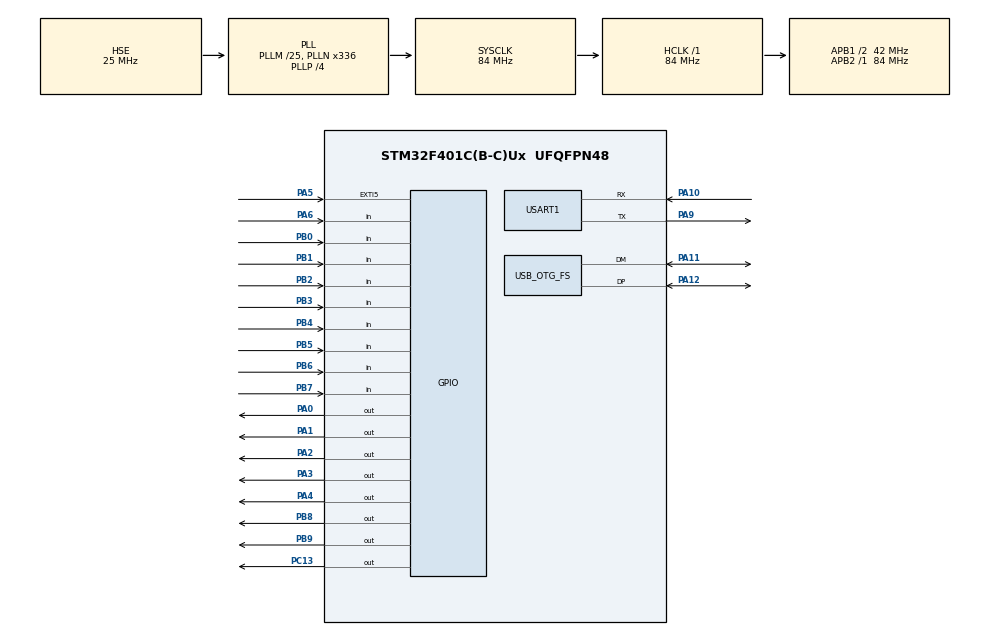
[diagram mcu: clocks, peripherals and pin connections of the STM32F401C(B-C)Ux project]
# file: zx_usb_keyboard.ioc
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Mcu.Family=STM32F4
Mcu.Name=STM32F401C(B-C)Ux
Mcu.Package=UFQFPN48
NVIC.EXTI9_5_IRQn=true\:0\:0\:false\:false\:true\:true\:true\:true
NVIC.OTG_FS_IRQn=true\:1\:0\:true\:false\:true\:false\:true\:true
NVIC.PriorityGroup=NVIC_PRIORITYGROUP_4
PA0-WKUP.GPIO_Speed=GPIO_SPEED_FREQ_VERY_HIGH
PA0-WKUP.PinState=GPIO_PIN_SET
PA0-WKUP.Signal=GPIO_Output
PA1.GPIO_Speed=GPIO_SPEED_FREQ_VERY_HIGH
PA1.PinState=GPIO_PIN_SET
PA1.Signal=GPIO_Output
PA10.Mode=Asynchronous
PA10.Signal=USART1_RX
PA11.Mode=Host_Only
PA11.Signal=USB_OTG_FS_DM
PA12.Mode=Host_Only
PA12.Signal=USB_OTG_FS_DP
PA13.Mode=Serial_Wire
PA13.Signal=SYS_JTMS-SWDIO
PA14.Mode=Serial_Wire
PA14.Signal=SYS_JTCK-SWCLK
PA2.GPIO_Speed=GPIO_SPEED_FREQ_VERY_HIGH
PA2.PinState=GPIO_PIN_SET
PA2.Signal=GPIO_Output
PA3.GPIO_Speed=GPIO_SPEED_FREQ_VERY_HIGH
PA3.PinState=GPIO_PIN_SET
PA3.Signal=GPIO_Output
PA4.GPIO_Speed=GPIO_SPEED_FREQ_VERY_HIGH
PA4.PinState=GPIO_PIN_SET
PA4.Signal=GPIO_Output
PA5.GPIO_ModeDefaultEXTI=GPIO_MODE_IT_FALLING
PA5.Signal=GPXTI5
PA6.Signal=GPIO_Input
PA9.Mode=Asynchronous
PA9.Signal=USART1_TX
PB0.Signal=GPIO_Input
PB1.Signal=GPIO_Input
PB2.Signal=GPIO_Input
PB3.Signal=GPIO_Input
PB4.Signal=GPIO_Input
PB5.Signal=GPIO_Input
PB6.Signal=GPIO_Input
PB7.Signal=GPIO_Input
PB8.GPIO_ModeDefaultOutputPP=GPIO_MODE_OUTPUT_OD
PB8.GPIO_PuPd=GPIO_NOPULL
PB8.GPIO_Speed=GPIO_SPEED_FREQ_VERY_HIGH
PB8.PinState=GPIO_PIN_SET
PB8.Signal=GPIO_Output
PB9.GPIO_ModeDefaultOutputPP=GPIO_MODE_OUTPUT_OD
PB9.GPIO_PuPd=GPIO_NOPULL
PB9.GPIO_Speed=GPIO_SPEED_FREQ_VERY_HIGH
PB9.PinState=GPIO_PIN_SET
PB9.Signal=GPIO_Output
PC13-ANTI_TAMP.PinState=GPIO_PIN_SET
PC13-ANTI_TAMP.Signal=GPIO_Output
PH0\ -\ OSC_IN.Mode=HSE-External-Oscillator
PH0\ -\ OSC_IN.Signal=RCC_OSC_IN
PH1\ -\ OSC_OUT.Mode=HSE-External-Oscillator
PH1\ -\ OSC_OUT.Signal=RCC_OSC_OUT
ProjectManager.HeapSize=0x200
ProjectManager.StackSize=0x400
ProjectManager.TargetToolchain=Makefile
RCC.48MHZClocksFreq_Value=48000000
RCC.AHBFreq_Value=84000000
RCC.APB1CLKDivider=RCC_HCLK_DIV2
RCC.APB1Freq_Value=42000000
RCC.APB1TimFreq_Value=84000000
RCC.APB2Freq_Value=84000000
RCC.APB2TimFreq_Value=84000000
RCC.CortexFreq_Value=84000000
RCC.HCLKFreq_Value=84000000
RCC.HSE_VALUE=25000000
RCC.HSI_VALUE=16000000
RCC.LSE_VALUE=32768
RCC.PLLM=25
RCC.PLLN=336
RCC.PLLP=RCC_PLLP_DIV4
RCC.PLLQ=7
RCC.SYSCLKFreq_VALUE=84000000
RCC.SYSCLKSource=RCC_SYSCLKSOURCE_PLLCLK
RCC.VCOOutputFreq_Value=336000000
USART1.VirtualMode=VM_ASYNC
USB_HOST.USBH_HandleTypeDef=hUsbHostFS
USB_HOST.VirtualModeFS=Hid
USB_OTG_FS.VirtualMode=Host_Only
USB_OTG_FS.phy_itface=HCD_PHY_EMBEDDED
VP_USB_HOST_VS_USB_HOST_HID_FS.Mode=HID_FS
board=custom

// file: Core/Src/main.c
/* USER CODE BEGIN Header */
/**
  ******************************************************************************
  * @file           : main.c
  * @brief          : Main program body
  ******************************************************************************
  * @attention
  *
  * Copyright (c) 2023 STMicroelectronics.
  * All rights reserved.
  *
  * This software is licensed under terms that can be found in the LICENSE file
  * in the root directory of this software component.
  * If no LICENSE file comes with this software, it is provided AS-IS.
  *
  ******************************************************************************
  */
/* USER CODE END Header */
#include "main.h"
#include "usb_host.h"

/* USER CODE BEGIN Includes */
#include "my.h"
/* USER CODE END Includes */

UART_HandleTypeDef huart1;

void SystemClock_Config(void);
static void MX_GPIO_Init(void);
static void MX_USART1_UART_Init(void);
void MX_USB_HOST_Process(void);

int main(void)
{

  /* MCU Configuration--------------------------------------------------------*/

  /* Reset of all peripherals, Initializes the Flash interface and the Systick. */
  HAL_Init();

  /* Configure the system clock */
  SystemClock_Config();

  /* Initialize all configured peripherals */
  MX_GPIO_Init();
  MX_USART1_UART_Init();
  MX_USB_HOST_Init();
  /* USER CODE BEGIN 2 */
  MyInit();
  /* USER CODE END 2 */

  /* Infinite loop */
  while (1)
  {
    MX_USB_HOST_Process();

    /* USER CODE BEGIN 3 */
    MyIdle();
  }
  /* USER CODE END 3 */
}

void SystemClock_Config(void)
{
  RCC_OscInitTypeDef RCC_OscInitStruct = {0};
  RCC_ClkInitTypeDef RCC_ClkInitStruct = {0};

  /** Configure the main internal regulator output voltage
  */
  __HAL_RCC_PWR_CLK_ENABLE();
  __HAL_PWR_VOLTAGESCALING_CONFIG(PWR_REGULATOR_VOLTAGE_SCALE2);

  /** Initializes the RCC Oscillators according to the specified parameters
  * in the RCC_OscInitTypeDef structure.
  */
  RCC_OscInitStruct.OscillatorType = RCC_OSCILLATORTYPE_HSE;
  RCC_OscInitStruct.HSEState = RCC_HSE_ON;
  RCC_OscInitStruct.PLL.PLLState = RCC_PLL_ON;
  RCC_OscInitStruct.PLL.PLLSource = RCC_PLLSOURCE_HSE;
  RCC_OscInitStruct.PLL.PLLM = 25;
  RCC_OscInitStruct.PLL.PLLN = 336;
  RCC_OscInitStruct.PLL.PLLP = RCC_PLLP_DIV4;
  RCC_OscInitStruct.PLL.PLLQ = 7;
  if (HAL_RCC_OscConfig(&RCC_OscInitStruct) != HAL_OK)
  {
    Error_Handler();
  }

  /** Initializes the CPU, AHB and APB buses clocks
  */
  RCC_ClkInitStruct.ClockType = RCC_CLOCKTYPE_HCLK|RCC_CLOCKTYPE_SYSCLK
                              |RCC_CLOCKTYPE_PCLK1|RCC_CLOCKTYPE_PCLK2;
  RCC_ClkInitStruct.SYSCLKSource = RCC_SYSCLKSOURCE_PLLCLK;
  RCC_ClkInitStruct.AHBCLKDivider = RCC_SYSCLK_DIV1;
  RCC_ClkInitStruct.APB1CLKDivider = RCC_HCLK_DIV2;
  RCC_ClkInitStruct.APB2CLKDivider = RCC_HCLK_DIV1;

  if (HAL_RCC_ClockConfig(&RCC_ClkInitStruct, FLASH_LATENCY_2) != HAL_OK)
  {
    Error_Handler();
  }
}

static void MX_USART1_UART_Init(void)
{

  huart1.Instance = USART1;
  huart1.Init.BaudRate = 115200;
  huart1.Init.WordLength = UART_WORDLENGTH_8B;
  huart1.Init.StopBits = UART_STOPBITS_1;
  huart1.Init.Parity = UART_PARITY_NONE;
  huart1.Init.Mode = UART_MODE_TX_RX;
  huart1.Init.HwFlowCtl = UART_HWCONTROL_NONE;
  huart1.Init.OverSampling = UART_OVERSAMPLING_16;
  if (HAL_UART_Init(&huart1) != HAL_OK)
  {
    Error_Handler();
  }

}

static void MX_GPIO_Init(void)
{
  GPIO_InitTypeDef GPIO_InitStruct = {0};

  /* GPIO Ports Clock Enable */
  __HAL_RCC_GPIOC_CLK_ENABLE();
  __HAL_RCC_GPIOH_CLK_ENABLE();
  __HAL_RCC_GPIOA_CLK_ENABLE();
  __HAL_RCC_GPIOB_CLK_ENABLE();

  /*Configure GPIO pin Output Level */
  HAL_GPIO_WritePin(GPIOC, GPIO_PIN_13, GPIO_PIN_SET);

  /*Configure GPIO pin Output Level */
  HAL_GPIO_WritePin(GPIOA, GPIO_PIN_0|GPIO_PIN_1|GPIO_PIN_2|GPIO_PIN_3
                          |GPIO_PIN_4, GPIO_PIN_SET);

  /*Configure GPIO pin Output Level */
  HAL_GPIO_WritePin(GPIOB, GPIO_PIN_8|GPIO_PIN_9, GPIO_PIN_SET);

  /*Configure GPIO pin : PC13 */
  GPIO_InitStruct.Pin = GPIO_PIN_13;
  GPIO_InitStruct.Mode = GPIO_MODE_OUTPUT_PP;
  GPIO_InitStruct.Pull = GPIO_NOPULL;
  GPIO_InitStruct.Speed = GPIO_SPEED_FREQ_LOW;
  HAL_GPIO_Init(GPIOC, &GPIO_InitStruct);

  /*Configure GPIO pins : PA0 PA1 PA2 PA3
                           PA4 */
  GPIO_InitStruct.Pin = GPIO_PIN_0|GPIO_PIN_1|GPIO_PIN_2|GPIO_PIN_3
                          |GPIO_PIN_4;
  GPIO_InitStruct.Mode = GPIO_MODE_OUTPUT_PP;
  GPIO_InitStruct.Pull = GPIO_NOPULL;
  GPIO_InitStruct.Speed = GPIO_SPEED_FREQ_VERY_HIGH;
  HAL_GPIO_Init(GPIOA, &GPIO_InitStruct);

  /*Configure GPIO pin : PA5 */
  GPIO_InitStruct.Pin = GPIO_PIN_5;
  GPIO_InitStruct.Mode = GPIO_MODE_IT_FALLING;
  GPIO_InitStruct.Pull = GPIO_NOPULL;
  HAL_GPIO_Init(GPIOA, &GPIO_InitStruct);

  /*Configure GPIO pin : PA6 */
  GPIO_InitStruct.Pin = GPIO_PIN_6;
  GPIO_InitStruct.Mode = GPIO_MODE_INPUT;
  GPIO_InitStruct.Pull = GPIO_NOPULL;
  HAL_GPIO_Init(GPIOA, &GPIO_InitStruct);

  /*Configure GPIO pins : PB0 PB1 PB2 PB3
                           PB4 PB5 PB6 PB7 */
  GPIO_InitStruct.Pin = GPIO_PIN_0|GPIO_PIN_1|GPIO_PIN_2|GPIO_PIN_3
                          |GPIO_PIN_4|GPIO_PIN_5|GPIO_PIN_6|GPIO_PIN_7;
  GPIO_InitStruct.Mode = GPIO_MODE_INPUT;
  GPIO_InitStruct.Pull = GPIO_NOPULL;
  HAL_GPIO_Init(GPIOB, &GPIO_InitStruct);

  /*Configure GPIO pins : PB8 PB9 */
  GPIO_InitStruct.Pin = GPIO_PIN_8|GPIO_PIN_9;
  GPIO_InitStruct.Mode = GPIO_MODE_OUTPUT_OD;
  GPIO_InitStruct.Pull = GPIO_NOPULL;
  GPIO_InitStruct.Speed = GPIO_SPEED_FREQ_VERY_HIGH;
  HAL_GPIO_Init(GPIOB, &GPIO_InitStruct);

  /* EXTI interrupt init*/
  HAL_NVIC_SetPriority(EXTI9_5_IRQn, 0, 0);
  HAL_NVIC_EnableIRQ(EXTI9_5_IRQn);

}

void Error_Handler(void)
{
  __disable_irq();
  while (1)
  {
  }
}
